# CY8C5888LTI_LP097 register map
File version: 0.1
Registers are 8-bit, read-write, no defined reset value unless marked. A register's access mark holds for its fields unless they carry their own. Offsets are from the block's base; [hi:lo] are bit positions; {n}, {i} and the like mark numbered series; 'fields as' and 'values as' point back to an identical list.

## PWM_2
Base 0x00000000
0x40006528 PWM_2_COMPARE_Reg 16-bit — UDB.D0 - Assigned Compare Value
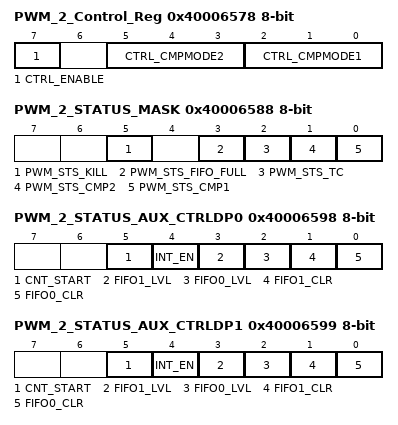
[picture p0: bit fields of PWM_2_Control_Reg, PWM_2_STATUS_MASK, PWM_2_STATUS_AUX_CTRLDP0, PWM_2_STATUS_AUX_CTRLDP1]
0x40006578 PWM_2_Control_Reg — UDB Control Register - Assigned Control Register Value
  [7] CTRL_ENABLE — Enable the PWM
  [5:3] CTRL_CMPMODE2 — Compare mode 2
  [2:0] CTRL_CMPMODE1 — Compare mode 1
0x40006588 PWM_2_STATUS_MASK — UDB Status bits Interrupt Mask Enable Register
  [5] PWM_STS_KILL ro — Enables the Interrupt on Kill
  [3] PWM_STS_FIFO_FULL ro — FIFO Full Status Mask
  [2] PWM_STS_TC ro — Enables the Interrupt on Terminal Count
  [1] PWM_STS_CMP2 ro — Enables the Interrupt on Compare 2
  [0] PWM_STS_CMP1 ro — Enables the Interrupt on Compare 1
0x40006598 PWM_2_STATUS_AUX_CTRLDP0 — UDB Auxilliary Control Register
  [5] CNT_START — FIFO0 clear
    0=E_CNT_START0 (Disable counter); 1=E_CNT_START1 (Enable counter)
  [4] INT_EN
    0=E_INT_EN0 (Interrupt disabled); 1=E_INT_EN1 (Interrupt enabled)
  [3] FIFO1_LVL — FIFO level
    0=E_FIFO_LVL_0 (FIFO LVL: input mode: FIFO not full; output mode: FIFO not empty); 1=E_FIFO_LVL_1 (FIFO LVL: input mode: FIFO at least 1/2 empty; output mode: FIFO at least 1/2 full)
  [2] FIFO0_LVL — FIFO level
    values as FIFO1_LVL
  [1] FIFO1_CLR — FIFO1 clear
    0=E_FIFO_CLR_0 (Normal FIFO operation); 1=E_FIFO_CLR_1 (Clear FIFO state)
  [0] FIFO0_CLR — FIFO0 clear
    values as FIFO1_CLR
0x40006599 PWM_2_STATUS_AUX_CTRLDP1 — UDB Auxilliary Control Register
  fields as PWM_2_STATUS_AUX_CTRLDP0

## PWM_3
Base 0x00000000
0x40006424 PWM_3_COMPARE_Reg 16-bit — UDB.D0 - Assigned Compare Value
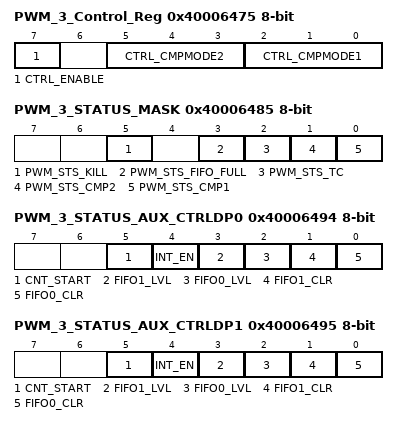
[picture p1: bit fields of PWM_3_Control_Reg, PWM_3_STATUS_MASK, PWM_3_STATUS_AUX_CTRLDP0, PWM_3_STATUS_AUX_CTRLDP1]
0x40006475 PWM_3_Control_Reg — UDB Control Register - Assigned Control Register Value
  [7] CTRL_ENABLE — Enable the PWM
  [5:3] CTRL_CMPMODE2 — Compare mode 2
  [2:0] CTRL_CMPMODE1 — Compare mode 1
0x40006485 PWM_3_STATUS_MASK — UDB Status bits Interrupt Mask Enable Register
  [5] PWM_STS_KILL ro — Enables the Interrupt on Kill
  [3] PWM_STS_FIFO_FULL ro — FIFO Full Status Mask
  [2] PWM_STS_TC ro — Enables the Interrupt on Terminal Count
  [1] PWM_STS_CMP2 ro — Enables the Interrupt on Compare 2
  [0] PWM_STS_CMP1 ro — Enables the Interrupt on Compare 1
0x40006494 PWM_3_STATUS_AUX_CTRLDP0 — UDB Auxilliary Control Register
  [5] CNT_START — FIFO0 clear
    0=E_CNT_START0 (Disable counter); 1=E_CNT_START1 (Enable counter)
  [4] INT_EN
    0=E_INT_EN0 (Interrupt disabled); 1=E_INT_EN1 (Interrupt enabled)
  [3] FIFO1_LVL — FIFO level
    0=E_FIFO_LVL_0 (FIFO LVL: input mode: FIFO not full; output mode: FIFO not empty); 1=E_FIFO_LVL_1 (FIFO LVL: input mode: FIFO at least 1/2 empty; output mode: FIFO at least 1/2 full)
  [2] FIFO0_LVL — FIFO level
    values as FIFO1_LVL
  [1] FIFO1_CLR — FIFO1 clear
    0=E_FIFO_CLR_0 (Normal FIFO operation); 1=E_FIFO_CLR_1 (Clear FIFO state)
  [0] FIFO0_CLR — FIFO0 clear
    values as FIFO1_CLR
0x40006495 PWM_3_STATUS_AUX_CTRLDP1 — UDB Auxilliary Control Register
  fields as PWM_3_STATUS_AUX_CTRLDP0

## UART
Base 0x00000000
0x40006448 TX_UART_TX_DATA — TX Data Register
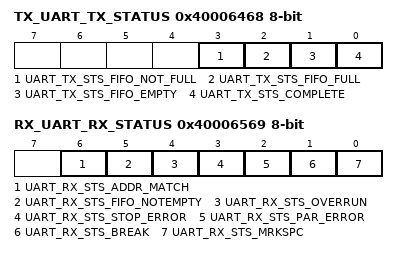
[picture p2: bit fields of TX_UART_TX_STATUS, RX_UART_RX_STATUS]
0x40006468 TX_UART_TX_STATUS — TX status register
  [3] UART_TX_STS_FIFO_NOT_FULL ro, [2] UART_TX_STS_FIFO_FULL ro, [1] UART_TX_STS_FIFO_EMPTY ro, [0] UART_TX_STS_COMPLETE ro
0x4000652A RX_UART_RX_ADDRESS1 — RX Address1 Register
0x4000653A RX_UART_RX_ADDRESS2 — RX Address2 Register
0x4000654A RX_UART_RX_DATA — RX Data Register
0x40006569 RX_UART_RX_STATUS — RX status register
  [6] UART_RX_STS_ADDR_MATCH ro, [5] UART_RX_STS_FIFO_NOTEMPTY ro, [4] UART_RX_STS_OVERRUN ro, [3] UART_RX_STS_STOP_ERROR ro, [2] UART_RX_STS_PAR_ERROR ro, [1] UART_RX_STS_BREAK ro, [0] UART_RX_STS_MRKSPC ro

## PWM_1
Base 0x00000000
0x4000642A PWM_1_COMPARE_Reg 16-bit — UDB.D0 - Assigned Compare Value
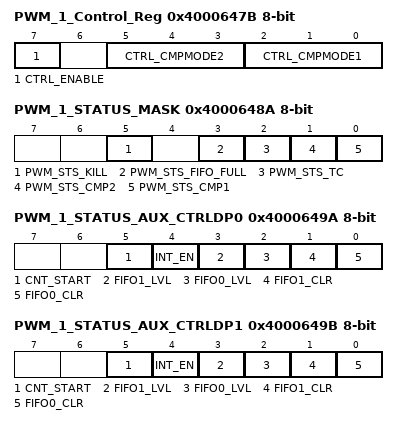
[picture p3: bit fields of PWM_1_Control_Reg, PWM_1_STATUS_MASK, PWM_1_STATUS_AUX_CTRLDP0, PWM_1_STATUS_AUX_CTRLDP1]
0x4000647B PWM_1_Control_Reg — UDB Control Register - Assigned Control Register Value
  [7] CTRL_ENABLE — Enable the PWM
  [5:3] CTRL_CMPMODE2 — Compare mode 2
  [2:0] CTRL_CMPMODE1 — Compare mode 1
0x4000648A PWM_1_STATUS_MASK — UDB Status bits Interrupt Mask Enable Register
  [5] PWM_STS_KILL ro — Enables the Interrupt on Kill
  [3] PWM_STS_FIFO_FULL ro — FIFO Full Status Mask
  [2] PWM_STS_TC ro — Enables the Interrupt on Terminal Count
  [1] PWM_STS_CMP2 ro — Enables the Interrupt on Compare 2
  [0] PWM_STS_CMP1 ro — Enables the Interrupt on Compare 1
0x4000649A PWM_1_STATUS_AUX_CTRLDP0 — UDB Auxilliary Control Register
  [5] CNT_START — FIFO0 clear
    0=E_CNT_START0 (Disable counter); 1=E_CNT_START1 (Enable counter)
  [4] INT_EN
    0=E_INT_EN0 (Interrupt disabled); 1=E_INT_EN1 (Interrupt enabled)
  [3] FIFO1_LVL — FIFO level
    0=E_FIFO_LVL_0 (FIFO LVL: input mode: FIFO not full; output mode: FIFO not empty); 1=E_FIFO_LVL_1 (FIFO LVL: input mode: FIFO at least 1/2 empty; output mode: FIFO at least 1/2 full)
  [2] FIFO0_LVL — FIFO level
    values as FIFO1_LVL
  [1] FIFO1_CLR — FIFO1 clear
    0=E_FIFO_CLR_0 (Normal FIFO operation); 1=E_FIFO_CLR_1 (Clear FIFO state)
  [0] FIFO0_CLR — FIFO0 clear
    values as FIFO1_CLR
0x4000649B PWM_1_STATUS_AUX_CTRLDP1 — UDB Auxilliary Control Register
  fields as PWM_1_STATUS_AUX_CTRLDP0

## ADC_0 — SAR ADC
Base 0x00000000
0x40004616 SAR_TR0 — SAR trim register
{0x40005908+i} SAR_CSR{i} (i=0..6) — SAR status and control register {i}
0x40005B28 SAR_SW0 — SAR Analog Routing Register 0
{0x40005B28+i} SAR_SW{i} (i=2..4) — SAR Analog Routing Register {i}
0x40005B2E SAR_SW6 — SAR Analog Routing Register 6
0x40005B2F SAR_CLK — SAR Clock Selection Register
0x40005BA2 SAR_WRK 16-bit — SAR working register

## PWM_0
Base 0x00000000
0x4000642C PWM_0_COMPARE_Reg 16-bit — UDB.D0 - Assigned Compare Value
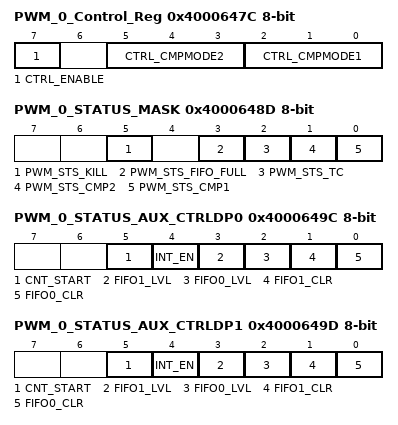
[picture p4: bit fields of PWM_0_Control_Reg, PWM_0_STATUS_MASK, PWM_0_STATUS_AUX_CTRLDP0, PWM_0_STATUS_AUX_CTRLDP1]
0x4000647C PWM_0_Control_Reg — UDB Control Register - Assigned Control Register Value
  [7] CTRL_ENABLE — Enable the PWM
  [5:3] CTRL_CMPMODE2 — Compare mode 2
  [2:0] CTRL_CMPMODE1 — Compare mode 1
0x4000648D PWM_0_STATUS_MASK — UDB Status bits Interrupt Mask Enable Register
  [5] PWM_STS_KILL ro — Enables the Interrupt on Kill
  [3] PWM_STS_FIFO_FULL ro — FIFO Full Status Mask
  [2] PWM_STS_TC ro — Enables the Interrupt on Terminal Count
  [1] PWM_STS_CMP2 ro — Enables the Interrupt on Compare 2
  [0] PWM_STS_CMP1 ro — Enables the Interrupt on Compare 1
0x4000649C PWM_0_STATUS_AUX_CTRLDP0 — UDB Auxilliary Control Register
  [5] CNT_START — FIFO0 clear
    0=E_CNT_START0 (Disable counter); 1=E_CNT_START1 (Enable counter)
  [4] INT_EN
    0=E_INT_EN0 (Interrupt disabled); 1=E_INT_EN1 (Interrupt enabled)
  [3] FIFO1_LVL — FIFO level
    0=E_FIFO_LVL_0 (FIFO LVL: input mode: FIFO not full; output mode: FIFO not empty); 1=E_FIFO_LVL_1 (FIFO LVL: input mode: FIFO at least 1/2 empty; output mode: FIFO at least 1/2 full)
  [2] FIFO0_LVL — FIFO level
    values as FIFO1_LVL
  [1] FIFO1_CLR — FIFO1 clear
    0=E_FIFO_CLR_0 (Normal FIFO operation); 1=E_FIFO_CLR_1 (Clear FIFO state)
  [0] FIFO0_CLR — FIFO0 clear
    values as FIFO1_CLR
0x4000649D PWM_0_STATUS_AUX_CTRLDP1 — UDB Auxilliary Control Register
  fields as PWM_0_STATUS_AUX_CTRLDP0
